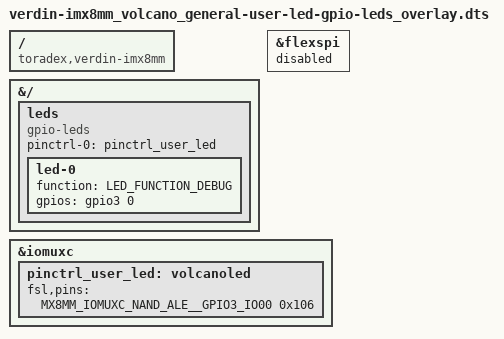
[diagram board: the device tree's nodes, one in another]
// SPDX-License-Identifier: GPL-2.0-or-later OR MIT

// General led on Embtech Volcano base board.

/dts-v1/;
/plugin/;

#include <dt-bindings/gpio/gpio.h>
#include <dt-bindings/interrupt-controller/irq.h>
#include <dt-bindings/leds/common.h>
#include <dt-bindings/../../arch/arm64/boot/dts/freescale/imx8mp-pinfunc.h>

/ {
	compatible = "toradex,verdin-imx8mm";
};

&{/} {
	leds {
		compatible = "gpio-leds";
		pinctrl-names = "default";
		pinctrl-0 = <&pinctrl_user_led>;

		/* SODIMM 52 - General use LED */
		led-0 {
				function = LED_FUNCTION_DEBUG;
				gpios = <&gpio3 0 GPIO_ACTIVE_HIGH>;
		};
	};
};

&flexspi {
	status = "disabled";
};

&iomuxc {
        pinctrl_user_led: volcanoled {
                fsl,pins = <
                        MX8MM_IOMUXC_NAND_ALE__GPIO3_IO00       0x106   /* SODIMM 52 */
                >;
        };
};
